# AT90PWM161 register map
Vendor: Atmel; File version: 1.0
CPU: other r0p0, little endian, no MPU, no FPU, 4 interrupt priority bits
Registers are 8-bit, read-write, reset 0x0 unless marked. A register's access mark holds for its fields unless they carry their own. Offsets are from the block's base; lines under a group give offsets from that group; [hi:lo] are bit positions; {n}, {i} and the like mark numbered series; 'fields as' and 'values as' point back to an identical list; <NAME> marks a mode.

## Memory map
0x00800000 FUSE size 0x3 — Fuses
0x00800000 LOCKBIT size 0x1 — Lockbits
0x00800020 AC blocks up to offset 0x60 — Analog Comparator
0x00800021 TC1 blocks up to offset 0x6D — Timer/Counter, 16-bit
0x00800023 PORTB size 0x3 — I/O Port
0x00800026 ADC blocks up to offset 0x54 — Analog-to-Digital Converter
0x00800029 PORTD size 0x3 — I/O Port
0x0080002C PORTE size 0x3 — I/O Port
0x0080002F PSC0 blocks up to offset 0x3C — Power Stage Controller
0x00800033 PSC2 blocks up to offset 0x3F — Power Stage Controller
0x00800037 SPI blocks up to offset 0x20 — Serial Peripheral Interface
0x00800039 CPU blocks up to offset 0x50 — CPU Registers
0x0080003C EEPROM size 0x4
0x00800040 EXINT blocks up to offset 0x4A — External Interrupts
0x00800057 BOOT_LOAD size 0x1 — Bootloader
0x00800058 DAC blocks up to offset 0x1F — Digital-to-Analog Converter
0x00800082 WDT size 0x1 — Watchdog Timer

## Interrupts
0 RESET (CPU) — External Pin, Power-on Reset, Brown-out Reset, Watchdog Reset and JTAG AVR Reset
1 PSC2_CAPT (CPU) — PSC2 Capture Event
2 PSC2_EC (CPU) — PSC2 End Cycle
3 PSC2_EEC (CPU) — PSC2 End Of Enhanced Cycle
4 PSC0_CAPT (CPU) — PSC0 Capture Event
5 PSC0_EC (CPU) — PSC0 End Cycle
6 PSC0_EEC (CPU) — PSC0 End Of Enhanced Cycle
7 ANALOG_COMP_1 (CPU) — Analog Comparator 1
8 ANALOG_COMP_2 (CPU) — Analog Comparator 2
9 ANALOG_COMP_3 (CPU) — Analog Comparator 3
10 INT0 (CPU) — External Interrupt Request 0
11 TIMER1_CAPT (CPU) — Timer/Counter1 Capture Event
12 TIMER1_OVF (CPU) — Timer/Counter1 Overflow
13 ADC (CPU) — ADC Conversion Complete
14 INT1 (CPU) — External Interrupt Request 1
15 SPI_STC (CPU) — SPI Serial Transfer Complet
16 INT2 (CPU) — External Interrupt Request 2
17 WDT (CPU) — Watchdog Timeout Interrupt
18 EE_READY (CPU) — EEPROM Ready
19 SPM_READY (CPU) — Store Program Memory Read

## AC — Analog Comparator
Base 0x00800020
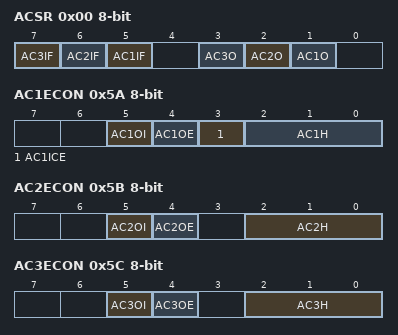
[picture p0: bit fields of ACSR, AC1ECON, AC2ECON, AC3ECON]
0x00 ACSR — Analog Comparator Status Register (read-only for debugger)
  [7] AC3IF — Analog Comparator 3 Interrupt Flag Bit
  [6] AC2IF — Analog Comparator 2 Interrupt Flag Bit
  [5] AC1IF — Analog Comparator 1 Interrupt Flag Bit
  [3] AC3O — Analog Comparator 3 Output Bit
  [2] AC2O — Analog Comparator 2 Output Bit
  [1] AC1O — Analog Comparator 1 Output Bit
0x5A AC1ECON
  [5] AC1OI — Analog Comparator Output Invert
  [4] AC1OE — Analog Comparator Output Enable
  [3] AC1ICE — Analog Comparator Interrupt Capture Enable
  [2:0] AC1H — Analog Comparator Hysteresis Select
0x5B AC2ECON
  [5] AC2OI — Analog Comparator Output Invert
  [4] AC2OE — Analog Comparator Output Enable
  [2:0] AC2H — Analog Comparator Hysteresis Select
0x5C AC3ECON
  [5] AC3OI — Analog Comparator Output Invert
  [4] AC3OE — Analog Comparator Output Enable
  [2:0] AC3H — Analog Comparator Hysteresis Select
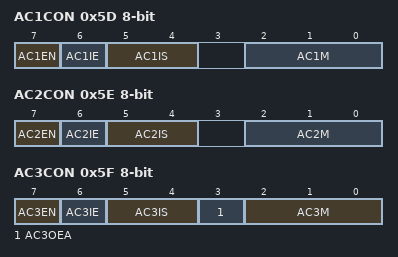
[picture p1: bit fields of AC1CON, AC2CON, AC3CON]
0x5D AC1CON — Analog Comparator 1 Control Register
  [7] AC1EN — Analog Comparator 1 Enable Bit
  [6] AC1IE — Analog Comparator 1 Interrupt Enable Bit
  [5:4] AC1IS — Analog Comparator 1 Interrupt Select Bit
    0=INTERRUPT_ON_TOGGLE; 2=INTERRUPT_ON_FALLING_EDGE; 3=INTERRUPT_ON_RISING_EDGE
  [2:0] AC1M — Analog Comparator 1 Multiplexer Register
0x5E AC2CON — Analog Comparator 2 Control Register
  [7] AC2EN — Analog Comparator 2 Enable Bit
  [6] AC2IE — Analog Comparator 2 Interrupt Enable Bit
  [5:4] AC2IS — Analog Comparator 2 Interrupt Select Bit
    values as AC1CON.AC1IS
  [2:0] AC2M — Analog Comparator 2 Multiplexer Register
0x5F AC3CON — Analog Comparator3 Control Register
  [7] AC3EN — Analog Comparator3 Enable Bit
  [6] AC3IE — Analog Comparator 3 Interrupt Enable Bit
  [5:4] AC3IS — Analog Comparator 3 Interrupt Select Bit
  [3] AC3OEA — Analog Comparator 3 Alternate Output Enable
  [2:0] AC3M — Analog Comparator 3 Multiplexer Register
